# C7X256V_DEBUG_THINMAN_REG_000734000000h register map
Vendor: Texas Instruments
Peripheral module from a debugger description file (folder am62D).
Registers are 32-bit, read-write, reset 0x0 unless marked. A register's access mark holds for its fields unless they carry their own. Offsets are as the file gives them; lines under a group give offsets from that group; [hi:lo] are bit positions; {n}, {i} and the like mark numbered series; 'fields as' and 'values as' point back to an identical list; <NAME> marks a mode.

## thinman_reg
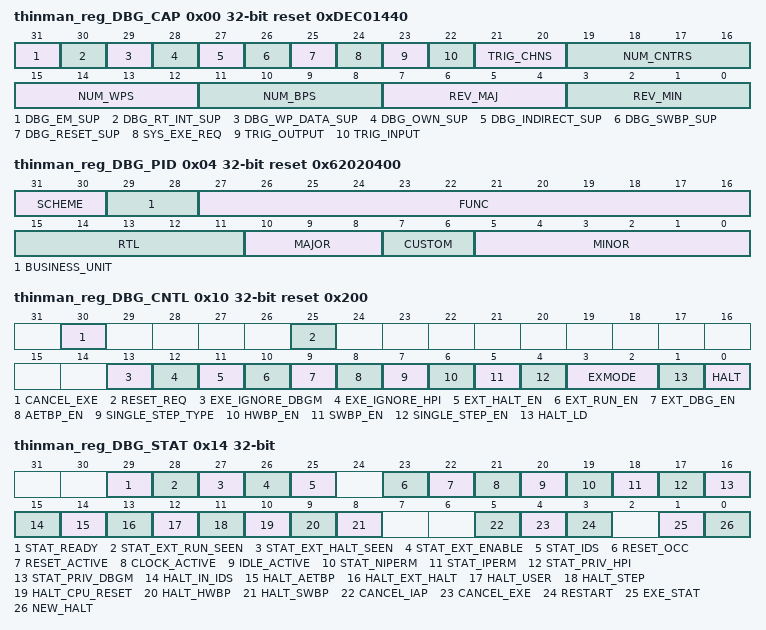
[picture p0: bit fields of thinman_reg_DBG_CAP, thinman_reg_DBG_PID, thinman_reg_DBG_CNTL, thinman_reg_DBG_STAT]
0x00 thinman_reg_DBG_CAP ro reset 0xDEC01440 — Debug Capabilities Register This register is used by debug software to determine which debug modules are present and how many instances of each module exist.
  [31] DBG_EM_SUP — EM Mode Support
  [30] DBG_RT_INT_SUP — RT Mode Support
  [29] DBG_WP_DATA_SUP — WP Data Qualification Support
  [28] DBG_OWN_SUP — Ownership Support
  [27] DBG_INDIRECT_SUP — Indirect Debug Memory Port Support
  [26] DBG_SWBP_SUP — SWBP Support
  [25] DBG_RESET_SUP — CPU Reset Support
  [24] SYS_EXE_REQ — IDLE Status and Control
  [23] TRIG_OUTPUT — Trigger Output
  [22] TRIG_INPUT — Trigger Input
  [21:20] TRIG_CHNS — Number of Trigger Channels Supported
  [19:16] NUM_CNTRS — Number of Counters Implemented
  [15:12] NUM_WPS — Number of HWWP modules implemented
  [11:8] NUM_BPS — Number of HWBP modules implemented
  [7:4] REV_MAJ — The Major Revision number of this module
  [3:0] REV_MIN — The Minor Revision number of this module The first minor revision will be 0000b
0x04 thinman_reg_DBG_PID ro reset 0x62020400 — ThinMan Peripheral Identification Register This register is used to identify this implementation of ThinMan.
  [31:30] SCHEME — Defines the scheme
  [29:28] BUSINESS_UNIT
  [27:16] FUNC — Functional Group
  [15:11] RTL — RTL Revision
  [10:8] MAJOR — Major Revision
  [7:6] CUSTOM
  [5:0] MINOR — Minor Revision
0x10 thinman_reg_DBG_CNTL reset 0x200 — Debug Control Register This register is used by debug software to control all of the basic debug functions.
  [30] CANCEL_EXE — Cancel Execution Control Request This bit is used to cancel an execution control request
  [25] RESET_REQ — CPU Reset Request
  [13] EXE_IGNORE_DBGM — Ignore DBGM When Halting This bit is used to grant privileges to ignore the DBGM flag when servicing an execution control command that halts code execution
  [12] EXE_IGNORE_HPI — Ignore HPI This bit determines if execution requests issued via DBG_CNTL will honor or ignore HPI state
  [11] EXT_HALT_EN — Enable for External Debug Halt Trigger This bit enables the use of the external debug halt trigger [dbg_halt_req] to support halting the CPU
  [10] EXT_RUN_EN — Enable for External Debug Run Trigger This bit enables the use of the external debug run trigger [dbg_run_req] to support running the CPU
  [9] EXT_DBG_EN — Enable for External Debug Enable This bit enables allows the use of the external debug enable qualifier [dbg_enable] to support debug when coming out of a non-functional state
  [8] AETBP_EN — AET Generated Breakpoint Halt Enable This bit enables halting on the AET imprecise breakpoint debug event
  [7] SINGLE_STEP_TYPE — Single Step Type This bit defines the interrupt behavior while single-stepping
  [6] HWBP_EN — Hardware Breakpoint Halt Enable NOTE: Each hardware breakpoint resource also has a local enable
  [5] SWBP_EN — Software Breakpoint Halt Enable This bit enables halting on software breakpoint detection NOTE: If a SWBP opcode is fetched when this enable bit is not set then it is executed as a NOP
  [4] SINGLE_STEP_EN — Single Step Execution Enable This bit enables single step operation NOTE: See DBG_CNTL:SINGLE_STEP_TYPE for additional information
  [3:2] EXMODE — Execution Mode This bit controls the setting of the execution mode
  [1] HALT_LD — Global Debug Run Control Load This bit determines if a DBG_CNTL register write can update the HALT field This bit is simply an enable during writes, has no storage, and is always read as zero
  [0] HALT — Global Debug Run Control This bit controls the global execution state This bit will be read as being set upon entry to HALTED state due to the halted state being entered because of a debug event
0x14 thinman_reg_DBG_STAT access per field — Debug Status Register This register provides all the required system state to the debug tools.
  [29] STAT_READY rw — Ready Status Continuously Inactive [sticky] This bit indicates the ready status of the CPU and is used to detect a CPU hang condition It is a sticky bit A simultaneous set and clear condition causes the bit to be set
  [28] STAT_EXT_RUN_SEEN rw — External Run Trigger Status This bit indicates that a qualified external run trigger was detected since the last time it was cleared It is a sticky bit A simultaneous set and clear condition causes the bit to be set
  [27] STAT_EXT_HALT_SEEN rw — External Halt Trigger Status This bit indicates that a qualified external halt trigger was detected since the last time it was cleared It is a sticky bit A simultaneous set and clear condition causes the bit to be set
  [26] STAT_EXT_ENABLE ro — External Debug Enable Qualifier Status This bit indicates the state of the external debug enable qualifier
  [25] STAT_IDS ro — State of the Interrupt During Suspend CPU State This bit indicates that an interrupt during suspend [IDS] is being serviced by the CPU
  [23] RESET_OCC rw — CPU Reset Occurred [sticky] This bit is used to determine if the CPU reset has been active at least one clock since the last time it was cleared This is a sticky bit A simultaneous set and clear condition causes the bit to be set NOTE: This register has no reset value, instead it is affected by the occurrence of a CPU reset
  [22] RESET_ACTIVE ro — CPU Reset Status This bit indicates the reset state of the CPU core
  [21] CLOCK_ACTIVE rw — CPU Clocks Active [sticky] This is a sticky bit which is set when a rising edge is seen on the CPUs functional clock This is a sticky bit A simultaneous set and clear condition causes the bit to be set
  [20] IDLE_ACTIVE ro — CPU is IDLE This bit indicates the idle state of the CPU core
  [19] STAT_NIPERM ro — State of Non-Invasive Permissions This bit indicates whether the next execute packet has Non-Invasive Permissions It is used to detect that the CPU is executing code that is not allotted Non-Invasive Debug Permissions
  [18] STAT_IPERM ro — State of Invasive Permissions This bit indicates whether the next execute packet has Invasive Permissions It is used to detect that the CPU is executing secure code and can not be debugged
  [17] STAT_PRIV_HPI ro — State of the HPI Privilege Window This bit indicates that a high priority interrupt has been taken but has not yet been completed
  [16] STAT_PRIV_DBGM ro — State of the DBGM Privilege Window This bit reflects the state of the DBGM privilege window
  [15] HALT_IN_IDS ro — Execution Halted within an Interrupt During Suspend [IDS] This bit indicates that the CPU has halted while executing an IDS
  [14] HALT_AETBP ro — Execution Halted Due to an AET generated breakpoint This bit indicates that an AET-generated breakpoint has halted code execution
  [13] HALT_EXT_HALT ro — Execution Halted Due to an external debug halt request
  [12] HALT_USER ro — Execution Halted Due to a application update of the HALT bit
  [11] HALT_STEP ro — Execution Halted Due to a Single Step This bit indicates that the halt occurred due to the completion of a single step operation
  [10] HALT_CPU_RESET ro — Execution Halted Due to CPU Reset or a halt request made during CPU Reset
  [9] HALT_HWBP ro — Execution Halted Due to a Hardware Breakpoint This bit indicates that the halt occurred due to the detection of a hardware breakpoint
  [8] HALT_SWBP ro — Execution Halted Due to a SWBP This bit indicates that the halt occurred due to a software breakpoint being detected
  [5] CANCEL_IAP rw — Indirect Access Port Request Canceled This bit indicates that an IAP read or write request has been canceled [eg due to Port Reset, CPU Reset, New debug context] since the last time it was cleared It is a sticky bit A simultaneous set and clear condition causes the bit to be set
  [4] CANCEL_EXE rw — Debug Command Request Canceled This bit indicates that a debug request has been canceled [by a NEW_HALT or by DBG_CNTL:CANCEL_EXE while a previously issued command was pending] since the last time it was cleared It is a sticky bit A simultaneous set and clear condition causes the bit to be set
  [3] RESTART rw — Execution Restart This bit indicates that the core execution resumed due to a debug command since the last time it was cleared It is a sticky bit A simultaneous set and clear condition causes the bit to be set
  [1] EXE_STAT ro — Execution State This bit indicates the execution status of the CPU
  [0] NEW_HALT ro — Debug Context Status This bit indicates that the processor has halted at a new location [or debug context] relative to the previously active debug location
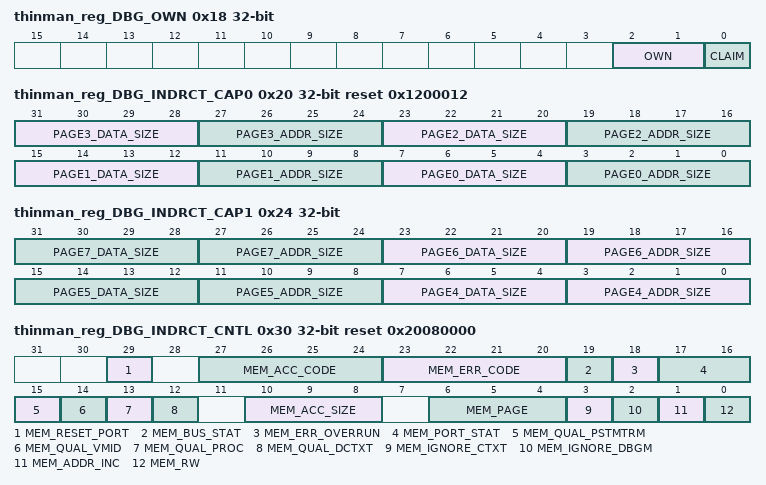
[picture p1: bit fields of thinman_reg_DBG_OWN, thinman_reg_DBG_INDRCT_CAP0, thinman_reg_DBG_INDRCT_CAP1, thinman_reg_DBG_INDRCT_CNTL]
0x18 thinman_reg_DBG_OWN — Ownership Control and Status Register
  [2:1] OWN — The Ownership State
  [0] CLAIM — This bit is used to obtain exclusive ownership of the debug module for either the debug initiator or the application initiator Reads will always return 0 If the current state is NOT_OWNED o A debugger-initiated write of 1 will claim the module for use by the debugger initiator o An application-initiated write of 1 will claim the module for use by the application initiator If the current state is DBG_OWNED o A debugger-initiated write of 0 will release ownership o A debugger-initiated write of 1 has no effect o Application writes have no effect If the current state is APP_OWNED o An application-initiated write of 0 will release ownership o A debugger-initiated write of 0 will release ownership o A write of 1 has not effect
0x20 thinman_reg_DBG_INDRCT_CAP0 ro reset 0x1200012 — Indirect Access Port Capabilities Register for Pages 0 - 3
  [31:28] PAGE3_DATA_SIZE — Page 3 is not implemented
  [27:24] PAGE3_ADDR_SIZE — Page 3 is not implemented
  [23:20] PAGE2_DATA_SIZE — Page 2 Data Size : CPU Registers
  [19:16] PAGE2_ADDR_SIZE — Page 2 Address Size : CPU Registers
  [15:12] PAGE1_DATA_SIZE — Page 1 is not implemented
  [11:8] PAGE1_ADDR_SIZE — Page 1 is not implemented
  [7:4] PAGE0_DATA_SIZE — Page 0 Data Size : Memory [Virtual]
  [3:0] PAGE0_ADDR_SIZE — Page 0 Address Size : Memory [Virtual]
0x24 thinman_reg_DBG_INDRCT_CAP1 ro — Indirect Access Port Capabilities Register for Pages 4 - 7
  [8n-25:8n-28] PAGE{n}_DATA_SIZE (n=4..7) — Page {n} is not implemented
  [8n-29:8n-32] PAGE{n}_ADDR_SIZE (n=4..7) — Page {n} is not implemented
0x30 thinman_reg_DBG_INDRCT_CNTL access per field reset 0x20080000 — Indirect Memory Control and Status Register This register is used to control the behavior of the indirect memory controller.
  [29] MEM_RESET_PORT rw — Port Reset
  [27:24] MEM_ACC_CODE ro — Indicates the access code returned for the last read transaction
  [23:20] MEM_ERR_CODE ro — Indicates the bus error code returned for a transaction This field indicates the memory access error code returned by the subsystem interconnect The first non-zero error is captured and held until it is cleared by a port reset
  [19] MEM_BUS_STAT ro — Indicates the bus status [ready state] of the processor interface selected by MEM_PAGE This bit indicates the current availability state [the bus ready value] for the interface selected by MEM_PAGE It is used by the debug agent to determine if the interface is in a hung state
  [18] MEM_ERR_OVERRUN ro — Indicates the state of the access port This field indicates that the settings of the indirect access port [control, context, data, or address] registers have changed before a previous access completed Once it is set to 1 it stays asserted until it is cleared by a port reset
  [17:16] MEM_PORT_STAT ro — Pending Memory Request Completed This bit indicates the status of the memory port
  [15] MEM_QUAL_PSTMTRM rw — Post Mortem Qualification This bit controls if a memory access is submitted as part of a postmortem analysis acitivty This bit will be set only when normal debug initiated accesses are no longer possible due to a system crash When set, the CPU will service an indirect access port request independent of all other memory qualifiers or normally required architectural state dependencies
  [14] MEM_QUAL_VMID rw — VMID Qualification This bit controls if a VMID context match is required of accesses submitted by the indirect controller The VMID reference is programmed using DBG_INDRCT_CTXT2
  [13] MEM_QUAL_PROC rw — Processor State Qualification Enable This bit controls if a processor state match is required of accesses submitted by the indirect controller The processor states of interest are programmed using DBG_INDRCT_CTXT2
  [12] MEM_QUAL_DCTXT rw — Debug Context Qualification Enable This bit controls if a DCTXT context match is required of accesses submitted by the indirect controller The DCTXT reference and mask are programmed using DBG_INDRCT_CTXT0 and DBG_INDRCT_CTXT1
  [10:8] MEM_ACC_SIZE rw — Access size of the next transaction
  [6:4] MEM_PAGE rw — Page designator for the next access This bit defines the page index of the memory page targeted for subsequent transactions The parameters of the pages supported in the system are available in the DBG_INDRCT_CAP register
  [3] MEM_IGNORE_CTXT rw — Ignore Context This bit determines whether memory/register accesses through the indirect controller will honor or ignore IDS and debug context changes
  [2] MEM_IGNORE_DBGM rw — Ignore DBGM When Halting This bit is used to grant privileges to ignore the DBGM flag when servicing a request to access memory or registers via the Indirect Access Port
  [1] MEM_ADDR_INC rw — Auto increment address on each access This bit determines if the address used for the memory access auto-increments For read transactions, the auto-increment occurs when the previous value is read from the data registers This will automatically launch another read transaction from the new address For write transactions, the auto-increment occurs when the write completes A new write is not launched until new data is written into the data registers The auto-increment feature is disabled on any error [the bit stays set] and is not re-enabled until the error is cleared
  [0] MEM_RW rw — R/W Control for next accesses This bit determines if the port is executing read or write operations
0x34 thinman_reg_DBG_INDRCT_CTXT0 — Indirect Memory Context ID Register 0 This register is used to designate the desired debug context of accesses initiated via the indirect access port mechanism. Context ID Register 0 holds the reference value for the CPU register DBGCTXT. When enabled (via DBG_INDRCT_CNTL::MEM_QUAL_DCTXT ) this register is used in conjunction with DBG_INDRCT_CTXT1 and the state of the CPU register DBGCTXT to determine if the debug context criteria for an indirect access port access is met.
  [31:0] DBGCTXT_MASK — This field is used to define the context qualification mask associated with DBG_INDRCT_CTXT0 An asserted bit means the corresponding DBGCTXT_REF bit is compared
0x38 thinman_reg_DBG_INDRCT_CTXT1 — Indirect Memory Context ID Register 1 This register is used to designate the desired debug context of accesses initiated via the indirect access port mechanism. Context ID Register 1 holds the MASK value for DBG_INDRCT_CTXT0.
  [31:0] DBGCTXT_REF — When used, this field is initialized with the DBGCTXT reference value
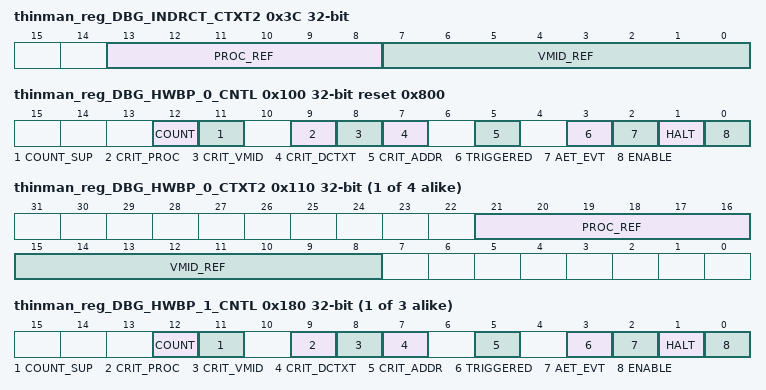
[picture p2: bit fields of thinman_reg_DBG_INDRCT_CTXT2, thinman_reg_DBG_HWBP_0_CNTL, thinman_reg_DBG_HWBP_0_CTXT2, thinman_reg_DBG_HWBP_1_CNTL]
0x3C thinman_reg_DBG_INDRCT_CTXT2 — Indirect Memory Context ID Register 2 This register is used to designate the desired debug context of accesses initiated via the indirect access port mechanism. Context ID Register 2 holds the context criteria for processor operating modes and the VMID. When enabled (via DBG_INDRCT_CNTL::MEM_QUAL_PROC and DBG_INDRCT_CNTL::MEM_QUAL_VMID) this register is used, in conjunction with current CPU state and VMID settings, to determine if the debug context criteria for an indirect access port access is met.
  [13:8] PROC_REF — Processor Mode Reference When enabled, this bit-field controls which processor modes the associated hardware breakpoint is active for -----0 : Inactive during Non-Root User -----1 : Active during Non-Root User ----0- : Inactive during Non-Root Supervisor ----1- : Active during Non-Root Supervisor ---0-- : Inactive during Root User ---1-- : Active during Root User --0--- : Inactive during Root Supervisor --1--- : Active during Root Supervisor -0---- : Inactive during Secure User -1---- : Active during Secure User 0----- : Inactive during Secure Supervisor 1----- : Active during Secure Supervisor
  [7:0] VMID_REF — When used, this field is initialized with the VMID reference
0x40 thinman_reg_DBG_INDRCT_ADDR0 — Indirect Memory Address Register 0
  [31:0] ADDR0 — Low order address bits for designating the target of an indirect debug access This bit field holds the 32 LSBs of the address of an indirect debug port transaction If the port is set for auto-incrementing addresses [DBG_INDRCT_CNTL:MEM_INC_ADDR = 1], this field will be incremented by the access size each time a transaction completes
0x44 thinman_reg_DBG_INDRCT_ADDR1 — Indirect Memory Address Register 1
  [31:0] ADDR1 — High order address bits for designating the target of an indirect debug access This bit field holds the 32 MSBs of the address of an indirect debug port transaction If the port is set for auto-incrementing addresses [DBG_INDRCT_CNTL:MEM_INC_ADDR = 1], this field will be incremented by one when the DBG_INDRCT_ADDR0 rolls over
0x48 thinman_reg_DBG_INDRCT_DATA0 — Indirect Memory Data Register 0 Data is packed using little endian byte numbering
  [31:0] DATA0 — Data bits of the read or write transaction This bit field holds bits 31:00 of the data of an indirect debug port transaction If Writing data: This register must be written after the address registers If Reading data This register will have valid read data when the transaction is complete [MEM_PORT_STAT == 10b]
0x4C thinman_reg_DBG_INDRCT_DATA1 — Indirect Memory Data Register 1 Data is packed using little endian byte numbering
  [31:0] DATA1 — Data bits of the read or write transaction This bit field holds bits 63:32 of the data of an indirect debug port transaction If Writing data: This register must be written after the address registers If Reading data This register will have valid read data when the transaction is complete [MEM_PORT_STAT == 10b]
0x100 thinman_reg_DBG_HWBP_0_CNTL access per field reset 0x800 — Hardware Breakpoint 0 Control Register This is the control and status register for hardware breakpoint resources.
  [12] COUNT rw — When implemented, this 20-bit count field defines the number of times an instruction address match is detected before the trigger is generated Writing n causes this hardware breakpoint resource to generate a trigger upon the [n+1]th occurrence of an instruction address match When set to 0 this hardware breakpoint resource will halt on the first occurrence of an instruction address match Reads return the current value of the supporting occurrence counter
  [11] COUNT_SUP ro — This bit defines whether this hardware breakpoint resource supports occurrence detection via the COUNT bit-field This bit is set by implementation
  [9] CRIT_PROC rw — This bit designates if the processor state match criteria is used to determine a comparison match
  [8] CRIT_VMID rw — This bit designates if the VMID match criteria is used to determine a comparison match
  [7] CRIT_DCTXT rw — This bit designates if the debug context match criteria is used to determine a comparison match
  [5] CRIT_ADDR rw — This bit designates if the address comparison criteria is used to determine a comparison match
  [3] TRIGGERED rw — This bit indicates that the trigger condition has been met since the last time this bit was cleared
  [2] AET_EVT rw — This bit configures the module to generate an AET event when triggered
  [1] HALT rw — This bit configures the module to halt the processor when triggered
  [0] ENABLE rw — This is the local enable for the hardware breakpoint module
0x108 thinman_reg_DBG_HWBP_0_CTXT0 — Hardware Breakpoint Context ID Register 0 This register is used to designate the desired context of the HWBP.
  fields as thinman_reg_DBG_INDRCT_CTXT1
{0x10C+0x80*i} thinman_reg_DBG_HWBP_{i}_CTXT1 (i=0..3) — Hardware Breakpoint Context ID Register 1 This register is used to designate the desired context of the HWBP.
  [31:0] CONTEXT_IDMASK — This field is used to define the context qualification mask associated with DBG_HWBP_0_ID0 An asserted bit means the corresponding CONTEXT_ID bit is compared
{0x110+0x80*i} thinman_reg_DBG_HWBP_{i}_CTXT2 (i=0..3) — Hardware Breakpoint Context ID Register 2 This register is used to designate the desired context of the HWBP.
  [21:16] PROC_REF — Processor Mode Reference When enabled, this bit-field controls which processor modes the associated hardware breakpoint is active for -----0 : Inactive during Non-Root User -----1 : Active during Non-Root User ----0- : Inactive during Non-Root Supervisor ----1- : Active during Non-Root Supervisor ---0-- : Inactive during Root User ---1-- : Active during Root User --0--- : Inactive during Root Supervisor --1--- : Active during Root Supervisor -0---- : Inactive during Secure User -1---- : Active during Secure User 0----- : Inactive during Secure Supervisor 1----- : Active during Secure Supervisor
  [15:8] VMID_REF — When used, this field is initialized with the VMID reference
{0x118+0x80*i} thinman_reg_DBG_HWBP_{i}_ADDR0 (i=0..3) — Hardware Breakpoint Address Register 0 This register is used to designate bits [31:2] of the execute packet address that this hardware breakpoint resource is detecting.
  [31:1] ADDR0 — Program Address Reference [31:2] This field is initialized with the most significant 30-bits of the least significant 32-bits of the execute packet in which this hardware breakpoint resource is detecting
{0x11C+0x80*i} thinman_reg_DBG_HWBP_{i}_ADDR1 (i=0..3) — Hardware Breakpoint Address Register 1 This register is used to designate bits [63:32] of the execute packet address that this hardware breakpoint resource is detecting.
  [31:0] ADDR1 — Program Address Reference [63:32] This field is initialized with the most significant 32-bits of a 64-bit address corresponding to the execute packet in which this hardware breakpoint resource is detecting
{0x120+0x80*i} thinman_reg_DBG_HWBP_{i}_AMASK0 reset 0xFFFFFFFE (i=0..3) — Hardware Breakpoint Address Mask Register 0 This register designates the LS 32-bits of the address qualifier mask
  [31:1] AMASK0 — Program Address Reference [63:32] This field is initialized with the most significant 32-bits of a 64-bit address corresponding to the execute packet in which this hardware breakpoint resource is detecting
{0x124+0x80*i} thinman_reg_DBG_HWBP_{i}_AMASK1 reset 0xFFFFFFFF (i=0..3) — Hardware Breakpoint Address Mask Register 1 This register designates the MS 32-bits of the address qualifier mask.
  [31:0] AMASK1 — Program Address Mask [63:32] This field is used as an address qualification mask for this hardware breakpoint resource An asserted bit means the corresponding address bit is compared
{0x100+0x80*i} thinman_reg_DBG_HWBP_{i}_CNTL access per field (i=1..3) — Hardware Breakpoint 0 Control Register This is the control and status register for hardware breakpoint resources.
  fields as thinman_reg_DBG_HWBP_0_CNTL
0x188 thinman_reg_DBG_HWBP_1_CTXT0 — Hardware Breakpoint Context ID Register 0 This register is used to designate the desired context of the HWBP.
  fields as thinman_reg_DBG_INDRCT_CTXT1
0x208 thinman_reg_DBG_HWBP_2_CTXT0 — Hardware Breakpoint Context ID Register 1 This register is used to designate the desired context of the HWBP.
  fields as thinman_reg_DBG_INDRCT_CTXT1
0x288 thinman_reg_DBG_HWBP_3_CTXT0 — Hardware Breakpoint Context ID Register 0 This register is used to designate the desired context of the HWBP.
  fields as thinman_reg_DBG_INDRCT_CTXT1
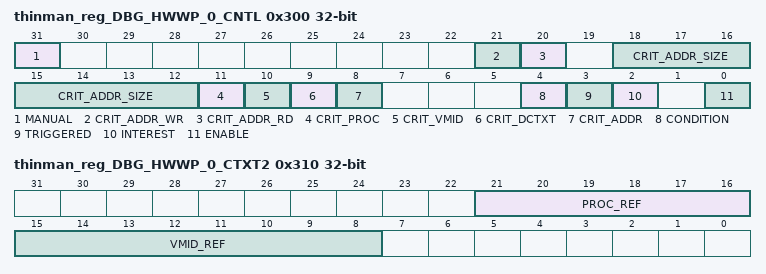
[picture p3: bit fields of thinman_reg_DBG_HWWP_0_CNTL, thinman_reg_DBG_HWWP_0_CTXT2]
0x300 thinman_reg_DBG_HWWP_0_CNTL — Hardware Watchpoint Control Register This is the control and status register for hardware watchpoint resource.
  [31] MANUAL — This bitfield provides a manual override to the generation of the hardware watchpoint trigger When set, the hardware watchpoint is continuously triggered
  [21] CRIT_ADDR_WR — This bitfield configures if data write requests [stores] are monitored to determine a comparison match when the address comparison criteria is enabled
  [20] CRIT_ADDR_RD — This bitfield configures if data read requests [loads] are monitored to determine a comparison match when the address comparison criteria is enabled
  [18:12] CRIT_ADDR_SIZE — This bitfield configures the size of the access used to determine a comparison match when the address comparison criteria is enabled ------0 : 8 bit acceses are not considered ------1 : 8 bit accesses are considered -----0- : 16-bit accesses are not considered -----1- : 16-bit accesses are considered ----0-- : 32-bit accesses are not considered ----1-- : 32-bit accesses are considered ---0--- : 64-bit accesses are not considered ---1--- : 64-bit accesses are considered --0---- : 128-bit accesses are not considered --1---- : 128-bit accesses are considered -0----- : 256-bit accesses are not considered -1----- : 256-bit accesses are considered 0------ : 512-bit accesses are not considered 1------ : 512-bit accesses are considered
  [11] CRIT_PROC — This bit designates if the processor state match criteria is used to determine a comparison match
  [10] CRIT_VMID — This bit designates if the VMID match criteria is used to determine a comparison match
  [9] CRIT_DCTXT — This bit designates if the debug context match criteria is used to determine a comparison match
  [8] CRIT_ADDR — This bit designates if the address comparison criteria is used to determine a comparison match
  [4] CONDITION — This bit defines the trigger condition that results in the generation of a trigger
  [3] TRIGGERED — This bit indicates that the trigger condition has been met since the last time this bit was cleared
  [2] INTEREST — This bit configures the module to generate an AET event when triggered
  [0] ENABLE — This is the local enable for the hardware watchpoint module
0x308 thinman_reg_DBG_HWWP_0_CTXT0 — Hardware Watchpoint Context ID Register 0 This register is used to designate the desired context of the HWWP.
  fields as thinman_reg_DBG_INDRCT_CTXT1
0x30C thinman_reg_DBG_HWWP_0_CTXT1 — Hardware Watchpoint Context ID Register 1 This register is used to designate the desired context of the HWWP.
  [31:0] CONTEXT_IDMASK — This field is used to define the context qualification mask associated with DBG_HWWP_0_ID0 An asserted bit means the corresponding CONTEXT_ID bit is compared
0x310 thinman_reg_DBG_HWWP_0_CTXT2 — Hardware Watchpoint Context ID Register 2 This register is used to designate the desired context of the HWWP.
  fields as thinman_reg_DBG_HWBP_0_CTXT2
0x318 thinman_reg_DBG_HWWP_0_ADDR0 — Hardware Watchpoint Address Register 0 This register is used to designate bits [31:0] of the address that this hardware watchpoint resource is detecting
  [31:0] ADDR0 — Address Reference [31:0] This field is initialized with the the least significant 32-bits of the address that this hardware watchpoint resource is detecting
0x31C thinman_reg_DBG_HWWP_0_ADDR1 — Hardware Watchpoint Address Register 1 This register is used to designate bits [63:32] of the address that this hardware watchpoint resource is detecting.
  [31:0] ADDR1 — Address Reference [63:32] This field is initialized with the the most significant 32-bits of the address that this hardware watchpoint resource is detecting
0x320 thinman_reg_DBG_HWWP_0_AMASK0 reset 0xFFFFFFFF — Hardware Breakpoint Watchpoint Mask Register 0 This register designates the LS 32-bits of the address qualifier mask
  [31:0] AMASK0 — Address Mask [31:2] This field is used as an address qualification mask for this hardware watchpoint resource An asserted bit means the corresponding address bit is compared
0x324 thinman_reg_DBG_HWWP_0_AMASK1 reset 0xFFFFFFFF — Hardware Watchpoint Address Mask Register 1 This register designates the MS 32-bits of the address qualifier m
  [31:0] AMASK1 — Address Mask [63:32] This field is used as an address qualification mask for this hardware watchpoint resource An asserted bit means the corresponding address bit is compared
